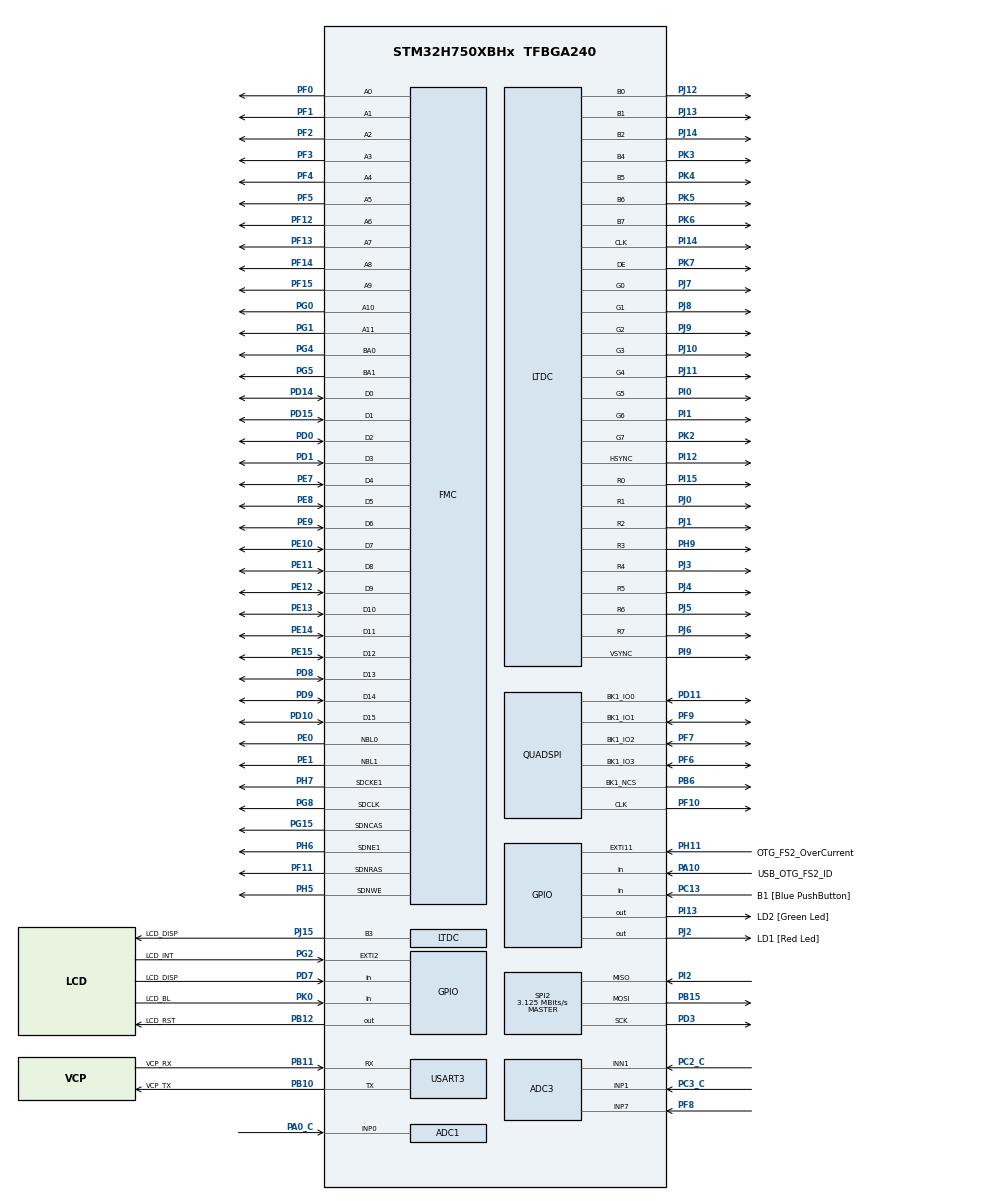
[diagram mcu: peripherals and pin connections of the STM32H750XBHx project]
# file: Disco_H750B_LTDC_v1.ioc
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ADC1.Channel-0\#ChannelRegularConversion=ADC_CHANNEL_0
ADC1.NbrOfConversionFlag=1
ADC1.OffsetNumber-0\#ChannelRegularConversion=ADC_OFFSET_NONE
ADC1.Rank-0\#ChannelRegularConversion=1
ADC1.SamplingTime-0\#ChannelRegularConversion=ADC_SAMPLETIME_1CYCLE_5
ADC1.master=1
ADC2.Channel-0\#ChannelRegularConversion=ADC_CHANNEL_0
ADC2.NbrOfConversionFlag=1
ADC2.OffsetNumber-0\#ChannelRegularConversion=ADC_OFFSET_NONE
ADC2.Rank-0\#ChannelRegularConversion=1
ADC2.SamplingTime-0\#ChannelRegularConversion=ADC_SAMPLETIME_1CYCLE_5
ADC3.Channel-0\#ChannelRegularConversion=ADC_CHANNEL_7
ADC3.NbrOfConversionFlag=1
ADC3.OffsetNumber-0\#ChannelRegularConversion=ADC_OFFSET_NONE
ADC3.Rank-0\#ChannelRegularConversion=1
ADC3.SamplingTime-0\#ChannelRegularConversion=ADC_SAMPLETIME_1CYCLE_5
Mcu.Family=STM32H7
Mcu.Name=STM32H750XBHx
Mcu.Package=TFBGA240
NVIC.PriorityGroup=NVIC_PRIORITYGROUP_4
PA0_C.Signal=ADCx_INP0
PA1.GPIO_Label=MII_RX_CLK
PA1.Signal=ETH_RX_CLK
PA10.GPIO_Label=USB_OTG_FS2_ID
PA10.Signal=GPIO_Input
PA11.GPIO_Label=USB_OTG_FS2_N
PA11.Signal=USB_OTG_FS_DM
PA12.GPIO_Label=USB_OTG_FS2_P
PA12.Signal=USB_OTG_FS_DP
PA1_C.Signal=ADCx_INP1
PA2.GPIO_Label=MII_MDIO
PA2.Signal=ETH_MDIO
PA6.Signal=S_TIM13_CH1
PA7.GPIO_Label=MII_RX_DV
PA7.Signal=ETH_RX_DV
PA8.Signal=S_TIM1_CH1
PA9.GPIO_Label=VBUS_FS2
PA9.Signal=USB_OTG_FS_VBUS
PB0.GPIO_Label=MII_RX_D2
PB0.Signal=ETH_RXD2
PB1.GPIO_Label=MII_RX_D3
PB1.Signal=ETH_RXD3
PB10.GPIO_Label=VCP_TX
PB10.Mode=Asynchronous
PB10.Signal=USART3_TX
PB11.GPIO_Label=VCP_RX
PB11.Mode=Asynchronous
PB11.Signal=USART3_RX
PB12.GPIO_Label=LCD_RST
PB12.Signal=GPIO_Output
PB13.GPIO_Label=FDCAN2_TX
PB13.Signal=FDCAN2_TX
PB15.Mode=Full_Duplex_Master
PB15.Signal=SPI2_MOSI
PB4\ (NJTRST).Signal=SPI2_NSS
PB5.GPIO_Label=FDCAN2_RX
PB5.Signal=FDCAN2_RX
PB6.Mode=Single Bank 1
PB6.Signal=QUADSPI_BK1_NCS
PB8.GPIO_Label=SDIO1_D4
PB8.Signal=SDMMC1_D4
PB9.GPIO_Label=SDIO1_D5
PB9.Signal=SDMMC1_D5
PC0.Signal=ADCx_INP10
PC1.GPIO_Label=MII_MDC
PC1.Signal=ETH_MDC
PC10.GPIO_Label=SDIO1_D2
PC10.Signal=SDMMC1_D2
PC11.GPIO_Label=SDIO1_D3
PC11.Signal=SDMMC1_D3
PC12.GPIO_Label=SDIO1_CK
PC12.Signal=SDMMC1_CK
PC13.GPIO_Label=B1 [Blue PushButton]
PC13.Signal=GPIO_Input
PC14-OSC32_IN\ (OSC32_IN).GPIO_Label=OSC32_IN
PC14-OSC32_IN\ (OSC32_IN).Mode=LSE-External-Clock-Source
PC14-OSC32_IN\ (OSC32_IN).Signal=RCC_OSC32_IN
PC15-OSC32_OUT\ (OSC32_OUT).GPIO_Label=OSC32_OUT
PC15-OSC32_OUT\ (OSC32_OUT).Signal=RCC_OSC32_OUT
PC2.GPIO_Label=MII_TXD2
PC2.Signal=ETH_TXD2
PC2_C.Signal=SharedAnalog_PC2
PC3.GPIO_Label=MII_TX_CLK
PC3.Signal=ETH_TX_CLK
PC3_C.Mode=IN1-Differential
PC3_C.Signal=ADC3_INP1
PC4.GPIO_Label=MII_RXD0
PC4.Signal=ETH_RXD0
PC5.GPIO_Label=MII_RXD1
PC5.Signal=ETH_RXD1
PC6.GPIO_Label=SDIO1_D6
PC6.Signal=SDMMC1_D6
PC7.GPIO_Label=SDIO1_D7
PC7.Signal=SDMMC1_D7
PC8.GPIO_Label=SDIO1_D0
PC8.Signal=SDMMC1_D0
PC9.GPIO_Label=SDIO1_D1
PC9.Signal=SDMMC1_D1
PD0.Signal=FMC_D2_DA2
PD1.Signal=FMC_D3_DA3
PD10.Signal=FMC_D15_DA15
PD11.Mode=Single Bank 1
PD11.Signal=QUADSPI_BK1_IO0
PD14.Signal=FMC_D0_DA0
PD15.Signal=FMC_D1_DA1
PD2.GPIO_Label=SDIO1_CMD
PD2.Signal=SDMMC1_CMD
PD3.Mode=Full_Duplex_Master
PD3.Signal=SPI2_SCK
PD7.GPIO_Label=LCD_DISP
PD7.Signal=GPIO_Input
PD8.Signal=FMC_D13_DA13
PD9.Signal=FMC_D14_DA14
PE0.Signal=FMC_NBL0
PE1.Signal=FMC_NBL1
PE10.Signal=FMC_D7_DA7
PE11.Signal=FMC_D8_DA8
PE12.Signal=FMC_D9_DA9
PE13.Signal=FMC_D10_DA10
PE14.Signal=FMC_D11_DA11
PE15.Signal=FMC_D12_DA12
PE2.GPIO_Label=MII_TXD3
PE2.Signal=ETH_TXD3
PE4.Signal=SAI4_D2
PE5.Signal=SAI4_CK2
PE7.Signal=FMC_D4_DA4
PE8.Signal=FMC_D5_DA5
PE9.Signal=FMC_D6_DA6
PF0.Signal=FMC_A0
PF1.Signal=FMC_A1
PF10.Mode=Single Bank 1
PF10.Signal=QUADSPI_CLK
PF11.Signal=FMC_SDNRAS
PF12.Signal=FMC_A6
PF13.Signal=FMC_A7
PF14.Signal=FMC_A8
PF15.Signal=FMC_A9
PF2.Signal=FMC_A2
PF3.Signal=FMC_A3
PF4.Signal=FMC_A4
PF5.Signal=FMC_A5
PF6.Mode=Single Bank 1
PF6.Signal=QUADSPI_BK1_IO3
PF7.Mode=Single Bank 1
PF7.Signal=QUADSPI_BK1_IO2
PF8.Mode=IN7-Single-Ended
PF8.Signal=ADC3_INP7
PF9.Mode=Single Bank 1
PF9.Signal=QUADSPI_BK1_IO1
PG0.Signal=FMC_A10
PG1.Signal=FMC_A11
PG10.Signal=SAI2_SD_B
PG11.GPIO_Label=MII_TX_EN
PG11.Signal=ETH_TX_EN
PG12.GPIO_Label=MII_TXD1
PG12.Signal=ETH_TXD1
PG13.GPIO_Label=MII_TXD0
PG13.Signal=ETH_TXD0
PG15.Signal=FMC_SDNCAS
PG2.GPIO_Label=LCD_INT
PG2.Signal=GPXTI2
PG4.Signal=FMC_A14_BA0
PG5.Signal=FMC_A15_BA1
PG8.Signal=FMC_SDCLK
PH0-OSC_IN\ (PH0).GPIO_Label=OSC_IN
PH0-OSC_IN\ (PH0).Mode=HSE-External-Clock-Source
PH0-OSC_IN\ (PH0).Signal=RCC_OSC_IN
PH1-OSC_OUT\ (PH1).GPIO_Label=OSC_OUT
PH1-OSC_OUT\ (PH1).Signal=RCC_OSC_OUT
PH11.GPIO_Label=OTG_FS2_OverCurrent
PH11.Signal=GPXTI11
PH13.GPIO_Label=FDCAN1_TX
PH13.Signal=FDCAN1_TX
PH14.GPIO_Label=FDCAN1_RX
PH14.Signal=FDCAN1_RX
PH15.Signal=TIM8_CH3N
PH2.GPIO_Label=MII_CRS
PH2.Signal=ETH_CRS
PH3.GPIO_Label=MII_COL
PH3.Signal=ETH_COL
PH5.Signal=FMC_SDNWE
PH6.Mode=SdramChipSelect2_1
PH6.Signal=FMC_SDNE1
PH7.Mode=SdramChipSelect2_1
PH7.Signal=FMC_SDCKE1
PH9.Mode=RGB888
PH9.Signal=LTDC_R3
PI0.Mode=RGB888
PI0.Signal=LTDC_G5
PI1.Mode=RGB888
PI1.Signal=LTDC_G6
PI10.GPIO_Label=MII_RX_ER
PI10.Signal=ETH_RX_ER
PI12.Mode=RGB888
PI12.Signal=LTDC_HSYNC
PI13.GPIO_Label=LD2 [Green Led]
PI13.Signal=GPIO_Output
PI14.Mode=RGB888
PI14.Signal=LTDC_CLK
PI15.Mode=RGB888
PI15.Signal=LTDC_R0
PI2.Mode=Full_Duplex_Master
PI2.Signal=SPI2_MISO
PI4.Signal=SAI2_MCLK_A
PI5.Signal=SAI2_SCK_A
PI6.Signal=SAI2_SD_A
PI7.Signal=SAI2_FS_A
PI9.Mode=RGB888
PI9.Signal=LTDC_VSYNC
PJ0.Mode=RGB888
PJ0.Signal=LTDC_R1
PJ1.Mode=RGB888
PJ1.Signal=LTDC_R2
PJ10.Mode=RGB888
PJ10.Signal=LTDC_G3
PJ11.Mode=RGB888
PJ11.Signal=LTDC_G4
PJ12.Mode=RGB888
PJ12.Signal=LTDC_B0
PJ13.Mode=RGB888
PJ13.Signal=LTDC_B1
PJ14.Mode=RGB888
PJ14.Signal=LTDC_B2
PJ15.GPIO_Label=LCD_DISP
PJ15.Mode=RGB888
PJ15.Signal=LTDC_B3
PJ2.GPIO_Label=LD1 [Red Led]
PJ2.Signal=GPIO_Output
PJ3.Mode=RGB888
PJ3.Signal=LTDC_R4
PJ4.Mode=RGB888
PJ4.Signal=LTDC_R5
PJ5.Mode=RGB888
PJ5.Signal=LTDC_R6
PJ6.Mode=RGB888
PJ6.Signal=LTDC_R7
PJ7.Mode=RGB888
PJ7.Signal=LTDC_G0
PJ8.Mode=RGB888
PJ8.Signal=LTDC_G1
PJ9.Mode=RGB888
PJ9.Signal=LTDC_G2
PK0.GPIO_Label=LCD_BL
PK0.Signal=GPIO_Input
PK2.Mode=RGB888
PK2.Signal=LTDC_G7
PK3.Mode=RGB888
PK3.Signal=LTDC_B4
PK4.Mode=RGB888
PK4.Signal=LTDC_B5
PK5.Mode=RGB888
PK5.Signal=LTDC_B6
PK6.Mode=RGB888
PK6.Signal=LTDC_B7
PK7.Mode=RGB888
PK7.Signal=LTDC_DE
ProjectManager.HeapSize=0x200
ProjectManager.StackSize=0x400
ProjectManager.TargetToolchain=STM32CubeIDE
RCC.ADCFreq_Value=30000000
RCC.APB1Freq_Value=100000000
RCC.APB2Freq_Value=100000000
RCC.APB3Freq_Value=100000000
RCC.APB4Freq_Value=100000000
RCC.CortexFreq_Value=200000000
RCC.DIVM1=10
RCC.DIVM2=2
RCC.DIVN1=160
RCC.DIVN2=12
RCC.DIVN3=192
RCC.DIVP2=5
RCC.DIVQ1=4
RCC.HCLKFreq_Value=100000000
RCC.HPRE=RCC_HCLK_DIV2
RCC.PLL2FRACN=0
RCC.PLL3FRACN=0
RCC.PLLFRACN=0
RCC.PLLSourceVirtual=RCC_PLLSOURCE_HSE
RCC.PWR_Regulator_Voltage_Scale=PWR_REGULATOR_VOLTAGE_SCALE2
RCC.SYSCLKFreq_VALUE=200000000
RCC.SYSCLKSource=RCC_SYSCLKSOURCE_PLLCLK
RCC.USART234578CLockSelection=RCC_USART234578CLKSOURCE_HSI
RCC.USBFreq_Value=100000000
SH.ADCx_INP0.0=ADC1_INP0,IN0-Single-Ended
SH.ADCx_INP0.1=ADC2_INP0,IN0-Single-Ended
SH.ADCx_INP1.0=ADC1_INP1
SH.ADCx_INP1.1=ADC2_INP1
SH.ADCx_INP10.0=ADC1_INP10
SH.ADCx_INP10.1=ADC3_INP10
SH.FMC_A0.0=FMC_A0,12b-sda1
SH.FMC_A1.0=FMC_A1,12b-sda1
SH.FMC_A10.0=FMC_A10,12b-sda1
SH.FMC_A11.0=FMC_A11,12b-sda1
SH.FMC_A14_BA0.0=FMC_BA0,FourSdramBanks1
SH.FMC_A15_BA1.0=FMC_BA1,FourSdramBanks1
SH.FMC_A2.0=FMC_A2,12b-sda1
SH.FMC_A3.0=FMC_A3,12b-sda1
SH.FMC_A4.0=FMC_A4,12b-sda1
SH.FMC_A5.0=FMC_A5,12b-sda1
SH.FMC_A6.0=FMC_A6,12b-sda1
SH.FMC_A7.0=FMC_A7,12b-sda1
SH.FMC_A8.0=FMC_A8,12b-sda1
SH.FMC_A9.0=FMC_A9,12b-sda1
SH.FMC_D0_DA0.0=FMC_D0,sd-16b-d1
SH.FMC_D10_DA10.0=FMC_D10,sd-16b-d1
SH.FMC_D11_DA11.0=FMC_D11,sd-16b-d1
SH.FMC_D12_DA12.0=FMC_D12,sd-16b-d1
SH.FMC_D13_DA13.0=FMC_D13,sd-16b-d1
SH.FMC_D14_DA14.0=FMC_D14,sd-16b-d1
SH.FMC_D15_DA15.0=FMC_D15,sd-16b-d1
SH.FMC_D1_DA1.0=FMC_D1,sd-16b-d1
SH.FMC_D2_DA2.0=FMC_D2,sd-16b-d1
SH.FMC_D3_DA3.0=FMC_D3,sd-16b-d1
SH.FMC_D4_DA4.0=FMC_D4,sd-16b-d1
SH.FMC_D5_DA5.0=FMC_D5,sd-16b-d1
SH.FMC_D6_DA6.0=FMC_D6,sd-16b-d1
SH.FMC_D7_DA7.0=FMC_D7,sd-16b-d1
SH.FMC_D8_DA8.0=FMC_D8,sd-16b-d1
SH.FMC_D9_DA9.0=FMC_D9,sd-16b-d1
SH.FMC_NBL0.0=FMC_NBL0,Sd2ByteEnable1
SH.FMC_NBL1.0=FMC_NBL1,Sd2ByteEnable1
SH.FMC_SDCLK.0=FMC_SDCLK,12b-sda1
SH.FMC_SDNCAS.0=FMC_SDNCAS,12b-sda1
SH.FMC_SDNRAS.0=FMC_SDNRAS,12b-sda1
SH.FMC_SDNWE.0=FMC_SDNWE,12b-sda1
SH.S_TIM13_CH1.0=TIM13_CH1
SH.S_TIM1_CH1.0=TIM1_CH1
SH.SharedAnalog_PC2.0=ADC3_INP0
SH.SharedAnalog_PC2.1=ADC3_INN1,IN1-Differential
SPI2.BaudRatePrescaler=SPI_BAUDRATEPRESCALER_32
SPI2.CalculateBaudRate=3.125 MBits/s
SPI2.DataSize=SPI_DATASIZE_8BIT
SPI2.Direction=SPI_DIRECTION_2LINES
SPI2.Mode=SPI_MODE_MASTER
SPI2.VirtualType=VM_MASTER
USART3.VirtualMode-Asynchronous=VM_ASYNC
VP_DMA2D_VS_DMA2D.Mode=DMA2D_Activate
board=STM32H750B-DK

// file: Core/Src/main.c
/* USER CODE BEGIN Header */
/**
  ******************************************************************************
  * @file           : main.c
  * @brief          : Main program body
  ******************************************************************************
  * @attention
  *
  * Copyright (c) 2022 STMicroelectronics.
  * All rights reserved.
  *
  * This software is licensed under terms that can be found in the LICENSE file
  * in the root directory of this software component.
  * If no LICENSE file comes with this software, it is provided AS-IS.
  *
  ******************************************************************************
  */
/* USER CODE END Header */
#include "main.h"

/* USER CODE BEGIN Includes */
#include <stdio.h>
#include "RGB565_320x240.h"
#include "L8_320x240.h"
/* USER CODE END Includes */

ADC_HandleTypeDef hadc1;
ADC_HandleTypeDef hadc2;
ADC_HandleTypeDef hadc3;

SPI_HandleTypeDef hspi2;

UART_HandleTypeDef huart3;

/* USER CODE BEGIN PV */
LTDC_HandleTypeDef LtdcHandle;

__IO uint32_t ReloadFlag = 0;

/* Pictures position */
uint32_t Xpos1 = 0;
uint32_t Xpos2 = 160;
uint32_t Ypos1 = 0;
uint32_t Ypos2 = 32;
/* USER CODE END PV */

void SystemClock_Config(void);
void PeriphCommonClock_Config(void);
static void MX_GPIO_Init(void);
static void MX_ADC1_Init(void);
static void MX_ADC2_Init(void);
static void MX_ADC3_Init(void);
static void MX_USART3_UART_Init(void);
static void MX_SPI2_Init(void);
/* USER CODE BEGIN PFP */
static void LCD_Config(void);
static void CPU_CACHE_Enable(void);
static void PicturesPosition(uint32_t* x1,
                         uint32_t* y1,
                         uint32_t* x2,
                         uint32_t* y2,
                         uint32_t index);

/* USER CODE END PFP */

/* USER CODE BEGIN 0 */
// WARNING UART3 is connected to st-link
// Properties -> Settings -> MCU_Settings -> select use float with printf
/*
 * USART6, BaudRate = 115200, WordLength = UART_WORDLENGTH_8B, StopBits = UART_STOPBITS_1;
 * */
int _write(int file, char *ptr, int len)
{
	HAL_UART_Transmit(&huart3,(uint8_t *)ptr, len, 10);
	return len;
}
/* USER CODE END 0 */

int main(void)
{
  /* USER CODE BEGIN 1 */
	 CPU_CACHE_Enable();
  /* USER CODE END 1 */

  /* MCU Configuration--------------------------------------------------------*/

  /* Reset of all peripherals, Initializes the Flash interface and the Systick. */
  HAL_Init();

  /* Configure the system clock */
  SystemClock_Config();

/* Configure the peripherals common clocks */
  PeriphCommonClock_Config();

  /* Initialize all configured peripherals */
  MX_GPIO_Init();
  MX_ADC1_Init();
  MX_ADC2_Init();
  MX_ADC3_Init();
  MX_USART3_UART_Init();
  MX_SPI2_Init();
  /* USER CODE BEGIN 2 */

  /* Configure LED2 */
  BSP_LED_Init(LED2);

  /*##-1- LCD Configuration ##################################################*/
  /* Configure 2 layers w/ Blending and CLUT loading for layer 1 */
  LCD_Config();

  /*##-2- CLUT Configuration #################################################*/
  HAL_LTDC_ConfigCLUT(&LtdcHandle, (uint32_t *)L8_320x240_CLUT, 256, 0);

  /*##-3- Enable CLUT For Layer 1 ############################################*/
  HAL_LTDC_EnableCLUT(&LtdcHandle, 0);

  /* USER CODE END 2 */

  /* Infinite loop */
  while (1)
  {

    /* USER CODE BEGIN 3 */
	  printf("inf loop\n");
	  for (int index = 0; index < 32; index++)
	    {
	      /* calculate new picture position */
	       PicturesPosition(&Xpos1, &Ypos1, &Xpos2, &Ypos2, (index+1));

	       /* reconfigure the layer1 position  without Reloading*/
	       HAL_LTDC_SetWindowPosition_NoReload(&LtdcHandle, Xpos1, Ypos1, 0);
	       /* reconfigure the layer2 position  without Reloading*/
	       HAL_LTDC_SetWindowPosition_NoReload(&LtdcHandle, Xpos2, Ypos2, 1);
	       /*Ask for LTDC reload within next vertical blanking*/
	       ReloadFlag = 0;
	       HAL_LTDC_Reload(&LtdcHandle,LTDC_RELOAD_VERTICAL_BLANKING);

	      while(ReloadFlag == 0)
	      {
	        /* wait till reload takes effect (in the next vertical blanking period) */
	      }
	    }
	    HAL_Delay(500);

	    for (int index = 0; index < 32; index++)
	    {
	      /* calculate new picture position */
	       PicturesPosition(&Xpos2, &Ypos2, &Xpos1, &Ypos1, (index+1));

	       /* reconfigure the layer1 position  without Reloading*/
	       HAL_LTDC_SetWindowPosition_NoReload(&LtdcHandle, Xpos1, Ypos1, 0);
	       /* reconfigure the layer2 position  without Reloading*/
	       HAL_LTDC_SetWindowPosition_NoReload(&LtdcHandle, Xpos2, Ypos2, 1);
	       /*Ask for LTDC reload within next vertical blanking*/
	       ReloadFlag = 0;
	       HAL_LTDC_Reload(&LtdcHandle,LTDC_RELOAD_VERTICAL_BLANKING);

	      while(ReloadFlag == 0)
	    {
	        /* wait till reload takes effect (in the next vertical blanking period) */
	    }
	  }
	    HAL_Delay(500);
	  }
  /* USER CODE END 3 */
}

void SystemClock_Config(void)
{
  RCC_OscInitTypeDef RCC_OscInitStruct = {0};
  RCC_ClkInitTypeDef RCC_ClkInitStruct = {0};

  /** Supply configuration update enable
  */
  HAL_PWREx_ConfigSupply(PWR_LDO_SUPPLY);

  /** Configure the main internal regulator output voltage
  */
  __HAL_PWR_VOLTAGESCALING_CONFIG(PWR_REGULATOR_VOLTAGE_SCALE2);

  while(!__HAL_PWR_GET_FLAG(PWR_FLAG_VOSRDY)) {}

  /** Macro to configure the PLL clock source
  */
  __HAL_RCC_PLL_PLLSOURCE_CONFIG(RCC_PLLSOURCE_HSE);

  /** Initializes the RCC Oscillators according to the specified parameters
  * in the RCC_OscInitTypeDef structure.
  */
  RCC_OscInitStruct.OscillatorType = RCC_OSCILLATORTYPE_HSI|RCC_OSCILLATORTYPE_HSE;
  RCC_OscInitStruct.HSEState = RCC_HSE_BYPASS;
  RCC_OscInitStruct.HSIState = RCC_HSI_DIV1;
  RCC_OscInitStruct.HSICalibrationValue = RCC_HSICALIBRATION_DEFAULT;
  RCC_OscInitStruct.PLL.PLLState = RCC_PLL_ON;
  RCC_OscInitStruct.PLL.PLLSource = RCC_PLLSOURCE_HSE;
  RCC_OscInitStruct.PLL.PLLM = 10;
  RCC_OscInitStruct.PLL.PLLN = 160;
  RCC_OscInitStruct.PLL.PLLP = 2;
  RCC_OscInitStruct.PLL.PLLQ = 4;
  RCC_OscInitStruct.PLL.PLLR = 2;
  RCC_OscInitStruct.PLL.PLLRGE = RCC_PLL1VCIRANGE_1;
  RCC_OscInitStruct.PLL.PLLVCOSEL = RCC_PLL1VCOWIDE;
  RCC_OscInitStruct.PLL.PLLFRACN = 0;
  if (HAL_RCC_OscConfig(&RCC_OscInitStruct) != HAL_OK)
  {
    Error_Handler();
  }

  /** Initializes the CPU, AHB and APB buses clocks
  */
  RCC_ClkInitStruct.ClockType = RCC_CLOCKTYPE_HCLK|RCC_CLOCKTYPE_SYSCLK
                              |RCC_CLOCKTYPE_PCLK1|RCC_CLOCKTYPE_PCLK2
                              |RCC_CLOCKTYPE_D3PCLK1|RCC_CLOCKTYPE_D1PCLK1;
  RCC_ClkInitStruct.SYSCLKSource = RCC_SYSCLKSOURCE_PLLCLK;
  RCC_ClkInitStruct.SYSCLKDivider = RCC_SYSCLK_DIV1;
  RCC_ClkInitStruct.AHBCLKDivider = RCC_HCLK_DIV2;
  RCC_ClkInitStruct.APB3CLKDivider = RCC_APB3_DIV1;
  RCC_ClkInitStruct.APB1CLKDivider = RCC_APB1_DIV1;
  RCC_ClkInitStruct.APB2CLKDivider = RCC_APB2_DIV1;
  RCC_ClkInitStruct.APB4CLKDivider = RCC_APB4_DIV1;

  if (HAL_RCC_ClockConfig(&RCC_ClkInitStruct, FLASH_LATENCY_1) != HAL_OK)
  {
    Error_Handler();
  }
}

void PeriphCommonClock_Config(void)
{
  RCC_PeriphCLKInitTypeDef PeriphClkInitStruct = {0};

  /** Initializes the peripherals clock
  */
  PeriphClkInitStruct.PeriphClockSelection = RCC_PERIPHCLK_ADC;
  PeriphClkInitStruct.PLL2.PLL2M = 2;
  PeriphClkInitStruct.PLL2.PLL2N = 12;
  PeriphClkInitStruct.PLL2.PLL2P = 5;
  PeriphClkInitStruct.PLL2.PLL2Q = 2;
  PeriphClkInitStruct.PLL2.PLL2R = 2;
  PeriphClkInitStruct.PLL2.PLL2RGE = RCC_PLL2VCIRANGE_3;
  PeriphClkInitStruct.PLL2.PLL2VCOSEL = RCC_PLL2VCOMEDIUM;
  PeriphClkInitStruct.PLL2.PLL2FRACN = 0;
  PeriphClkInitStruct.AdcClockSelection = RCC_ADCCLKSOURCE_PLL2;
  if (HAL_RCCEx_PeriphCLKConfig(&PeriphClkInitStruct) != HAL_OK)
  {
    Error_Handler();
  }
}

static void MX_ADC1_Init(void)
{

  ADC_MultiModeTypeDef multimode = {0};
  ADC_ChannelConfTypeDef sConfig = {0};

  /** Common config
  */
  hadc1.Instance = ADC1;
  hadc1.Init.ClockPrescaler = ADC_CLOCK_ASYNC_DIV2;
  hadc1.Init.Resolution = ADC_RESOLUTION_16B;
  hadc1.Init.ScanConvMode = ADC_SCAN_DISABLE;
  hadc1.Init.EOCSelection = ADC_EOC_SINGLE_CONV;
  hadc1.Init.LowPowerAutoWait = DISABLE;
  hadc1.Init.ContinuousConvMode = DISABLE;
  hadc1.Init.NbrOfConversion = 1;
  hadc1.Init.DiscontinuousConvMode = DISABLE;
  hadc1.Init.ExternalTrigConv = ADC_SOFTWARE_START;
  hadc1.Init.ExternalTrigConvEdge = ADC_EXTERNALTRIGCONVEDGE_NONE;
  hadc1.Init.ConversionDataManagement = ADC_CONVERSIONDATA_DR;
  hadc1.Init.Overrun = ADC_OVR_DATA_PRESERVED;
  hadc1.Init.LeftBitShift = ADC_LEFTBITSHIFT_NONE;
  hadc1.Init.OversamplingMode = DISABLE;
  if (HAL_ADC_Init(&hadc1) != HAL_OK)
  {
    Error_Handler();
  }

  /** Configure the ADC multi-mode
  */
  multimode.Mode = ADC_MODE_INDEPENDENT;
  if (HAL_ADCEx_MultiModeConfigChannel(&hadc1, &multimode) != HAL_OK)
  {
    Error_Handler();
  }

  /** Configure Regular Channel
  */
  sConfig.Channel = ADC_CHANNEL_0;
  sConfig.Rank = ADC_REGULAR_RANK_1;
  sConfig.SamplingTime = ADC_SAMPLETIME_1CYCLE_5;
  sConfig.SingleDiff = ADC_SINGLE_ENDED;
  sConfig.OffsetNumber = ADC_OFFSET_NONE;
  sConfig.Offset = 0;
  sConfig.OffsetSignedSaturation = DISABLE;
  if (HAL_ADC_ConfigChannel(&hadc1, &sConfig) != HAL_OK)
  {
    Error_Handler();
  }

}

static void MX_ADC2_Init(void)
{

  ADC_ChannelConfTypeDef sConfig = {0};

  /** Common config
  */
  hadc2.Instance = ADC2;
  hadc2.Init.ClockPrescaler = ADC_CLOCK_ASYNC_DIV2;
  hadc2.Init.Resolution = ADC_RESOLUTION_16B;
  hadc2.Init.ScanConvMode = ADC_SCAN_DISABLE;
  hadc2.Init.EOCSelection = ADC_EOC_SINGLE_CONV;
  hadc2.Init.LowPowerAutoWait = DISABLE;
  hadc2.Init.ContinuousConvMode = DISABLE;
  hadc2.Init.NbrOfConversion = 1;
  hadc2.Init.DiscontinuousConvMode = DISABLE;
  hadc2.Init.ExternalTrigConv = ADC_SOFTWARE_START;
  hadc2.Init.ExternalTrigConvEdge = ADC_EXTERNALTRIGCONVEDGE_NONE;
  hadc2.Init.ConversionDataManagement = ADC_CONVERSIONDATA_DR;
  hadc2.Init.Overrun = ADC_OVR_DATA_PRESERVED;
  hadc2.Init.LeftBitShift = ADC_LEFTBITSHIFT_NONE;
  hadc2.Init.OversamplingMode = DISABLE;
  if (HAL_ADC_Init(&hadc2) != HAL_OK)
  {
    Error_Handler();
  }

  /** Configure Regular Channel
  */
  sConfig.Channel = ADC_CHANNEL_0;
  sConfig.Rank = ADC_REGULAR_RANK_1;
  sConfig.SamplingTime = ADC_SAMPLETIME_1CYCLE_5;
  sConfig.SingleDiff = ADC_SINGLE_ENDED;
  sConfig.OffsetNumber = ADC_OFFSET_NONE;
  sConfig.Offset = 0;
  sConfig.OffsetSignedSaturation = DISABLE;
  if (HAL_ADC_ConfigChannel(&hadc2, &sConfig) != HAL_OK)
  {
    Error_Handler();
  }

}

static void MX_ADC3_Init(void)
{

  ADC_ChannelConfTypeDef sConfig = {0};

  /** Common config
  */
  hadc3.Instance = ADC3;
  hadc3.Init.Resolution = ADC_RESOLUTION_16B;
  hadc3.Init.ScanConvMode = ADC_SCAN_DISABLE;
  hadc3.Init.EOCSelection = ADC_EOC_SINGLE_CONV;
  hadc3.Init.LowPowerAutoWait = DISABLE;
  hadc3.Init.ContinuousConvMode = DISABLE;
  hadc3.Init.NbrOfConversion = 1;
  hadc3.Init.DiscontinuousConvMode = DISABLE;
  hadc3.Init.ExternalTrigConv = ADC_SOFTWARE_START;
  hadc3.Init.ExternalTrigConvEdge = ADC_EXTERNALTRIGCONVEDGE_NONE;
  hadc3.Init.ConversionDataManagement = ADC_CONVERSIONDATA_DR;
  hadc3.Init.Overrun = ADC_OVR_DATA_PRESERVED;
  hadc3.Init.LeftBitShift = ADC_LEFTBITSHIFT_NONE;
  hadc3.Init.OversamplingMode = DISABLE;
  if (HAL_ADC_Init(&hadc3) != HAL_OK)
  {
    Error_Handler();
  }

  /** Configure Regular Channel
  */
  sConfig.Channel = ADC_CHANNEL_7;
  sConfig.Rank = ADC_REGULAR_RANK_1;
  sConfig.SamplingTime = ADC_SAMPLETIME_1CYCLE_5;
  sConfig.SingleDiff = ADC_SINGLE_ENDED;
  sConfig.OffsetNumber = ADC_OFFSET_NONE;
  sConfig.Offset = 0;
  sConfig.OffsetSignedSaturation = DISABLE;
  if (HAL_ADC_ConfigChannel(&hadc3, &sConfig) != HAL_OK)
  {
    Error_Handler();
  }

}

static void MX_SPI2_Init(void)
{

  /* SPI2 parameter configuration*/
  hspi2.Instance = SPI2;
  hspi2.Init.Mode = SPI_MODE_MASTER;
  hspi2.Init.Direction = SPI_DIRECTION_2LINES;
  hspi2.Init.DataSize = SPI_DATASIZE_8BIT;
  hspi2.Init.CLKPolarity = SPI_POLARITY_LOW;
  hspi2.Init.CLKPhase = SPI_PHASE_1EDGE;
  hspi2.Init.NSS = SPI_NSS_SOFT;
  hspi2.Init.BaudRatePrescaler = SPI_BAUDRATEPRESCALER_32;
  hspi2.Init.FirstBit = SPI_FIRSTBIT_MSB;
  hspi2.Init.TIMode = SPI_TIMODE_DISABLE;
  hspi2.Init.CRCCalculation = SPI_CRCCALCULATION_DISABLE;
  hspi2.Init.CRCPolynomial = 0x0;
  hspi2.Init.NSSPMode = SPI_NSS_PULSE_ENABLE;
  hspi2.Init.NSSPolarity = SPI_NSS_POLARITY_LOW;
  hspi2.Init.FifoThreshold = SPI_FIFO_THRESHOLD_01DATA;
  hspi2.Init.TxCRCInitializationPattern = SPI_CRC_INITIALIZATION_ALL_ZERO_PATTERN;
  hspi2.Init.RxCRCInitializationPattern = SPI_CRC_INITIALIZATION_ALL_ZERO_PATTERN;
  hspi2.Init.MasterSSIdleness = SPI_MASTER_SS_IDLENESS_00CYCLE;
  hspi2.Init.MasterInterDataIdleness = SPI_MASTER_INTERDATA_IDLENESS_00CYCLE;
  hspi2.Init.MasterReceiverAutoSusp = SPI_MASTER_RX_AUTOSUSP_DISABLE;
  hspi2.Init.MasterKeepIOState = SPI_MASTER_KEEP_IO_STATE_DISABLE;
  hspi2.Init.IOSwap = SPI_IO_SWAP_DISABLE;
  if (HAL_SPI_Init(&hspi2) != HAL_OK)
  {
    Error_Handler();
  }

}

static void MX_USART3_UART_Init(void)
{

  huart3.Instance = USART3;
  huart3.Init.BaudRate = 115200;
  huart3.Init.WordLength = UART_WORDLENGTH_8B;
  huart3.Init.StopBits = UART_STOPBITS_1;
  huart3.Init.Parity = UART_PARITY_NONE;
  huart3.Init.Mode = UART_MODE_TX_RX;
  huart3.Init.HwFlowCtl = UART_HWCONTROL_NONE;
  huart3.Init.OverSampling = UART_OVERSAMPLING_16;
  huart3.Init.OneBitSampling = UART_ONE_BIT_SAMPLE_DISABLE;
  huart3.Init.ClockPrescaler = UART_PRESCALER_DIV1;
  huart3.AdvancedInit.AdvFeatureInit = UART_ADVFEATURE_NO_INIT;
  if (HAL_UART_Init(&huart3) != HAL_OK)
  {
    Error_Handler();
  }
  if (HAL_UARTEx_SetTxFifoThreshold(&huart3, UART_TXFIFO_THRESHOLD_1_8) != HAL_OK)
  {
    Error_Handler();
  }
  if (HAL_UARTEx_SetRxFifoThreshold(&huart3, UART_RXFIFO_THRESHOLD_1_8) != HAL_OK)
  {
    Error_Handler();
  }
  if (HAL_UARTEx_DisableFifoMode(&huart3) != HAL_OK)
  {
    Error_Handler();
  }

}

static void MX_GPIO_Init(void)
{
  GPIO_InitTypeDef GPIO_InitStruct = {0};

  /* GPIO Ports Clock Enable */
  __HAL_RCC_GPIOI_CLK_ENABLE();
  __HAL_RCC_GPIOB_CLK_ENABLE();
  __HAL_RCC_GPIOK_CLK_ENABLE();
  __HAL_RCC_GPIOG_CLK_ENABLE();
  __HAL_RCC_GPIOC_CLK_ENABLE();
  __HAL_RCC_GPIOE_CLK_ENABLE();
  __HAL_RCC_GPIOJ_CLK_ENABLE();
  __HAL_RCC_GPIOD_CLK_ENABLE();
  __HAL_RCC_GPIOH_CLK_ENABLE();
  __HAL_RCC_GPIOA_CLK_ENABLE();
  __HAL_RCC_GPIOF_CLK_ENABLE();

  /*Configure GPIO pin Output Level */
  HAL_GPIO_WritePin(LD2_GPIO_Port, LD2_Pin, GPIO_PIN_RESET);

  /*Configure GPIO pin Output Level */
  HAL_GPIO_WritePin(LD1_GPIO_Port, LD1_Pin, GPIO_PIN_RESET);

  /*Configure GPIO pin Output Level */
  HAL_GPIO_WritePin(LCD_RST_GPIO_Port, LCD_RST_Pin, GPIO_PIN_RESET);

  /*Configure GPIO pins : PI6 PI5 PI4 PI7 */
  GPIO_InitStruct.Pin = GPIO_PIN_6|GPIO_PIN_5|GPIO_PIN_4|GPIO_PIN_7;
  GPIO_InitStruct.Mode = GPIO_MODE_AF_PP;
  GPIO_InitStruct.Pull = GPIO_NOPULL;
  GPIO_InitStruct.Speed = GPIO_SPEED_FREQ_LOW;
  GPIO_InitStruct.Alternate = GPIO_AF10_SAI2;
  HAL_GPIO_Init(GPIOI, &GPIO_InitStruct);

  /*Configure GPIO pins : FDCAN2_RX_Pin FDCAN2_TX_Pin */
  GPIO_InitStruct.Pin = FDCAN2_RX_Pin|FDCAN2_TX_Pin;
  GPIO_InitStruct.Mode = GPIO_MODE_AF_PP;
  GPIO_InitStruct.Pull = GPIO_NOPULL;
  GPIO_InitStruct.Speed = GPIO_SPEED_FREQ_LOW;
  GPIO_InitStruct.Alternate = GPIO_AF9_FDCAN2;
  HAL_GPIO_Init(GPIOB, &GPIO_InitStruct);

  /*Configure GPIO pin : PG10 */
  GPIO_InitStruct.Pin = GPIO_PIN_10;
  GPIO_InitStruct.Mode = GPIO_MODE_AF_PP;
  GPIO_InitStruct.Pull = GPIO_NOPULL;
  GPIO_InitStruct.Speed = GPIO_SPEED_FREQ_LOW;
  GPIO_InitStruct.Alternate = GPIO_AF10_SAI2;
  HAL_GPIO_Init(GPIOG, &GPIO_InitStruct);

  /*Configure GPIO pins : SDIO1_D2_Pin SDIO1_D3_Pin SDIO1_CK_Pin SDIO1_D0_Pin
                           SDIO1_D1_Pin SDIO1_D7_Pin SDIO1_D6_Pin */
  GPIO_InitStruct.Pin = SDIO1_D2_Pin|SDIO1_D3_Pin|SDIO1_CK_Pin|SDIO1_D0_Pin
                          |SDIO1_D1_Pin|SDIO1_D7_Pin|SDIO1_D6_Pin;
  GPIO_InitStruct.Mode = GPIO_MODE_AF_PP;
  GPIO_InitStruct.Pull = GPIO_NOPULL;
  GPIO_InitStruct.Speed = GPIO_SPEED_FREQ_VERY_HIGH;
  GPIO_InitStruct.Alternate = GPIO_AF12_SDIO1;
  HAL_GPIO_Init(GPIOC, &GPIO_InitStruct);

  /*Configure GPIO pins : MII_TX_EN_Pin MII_TXD1_Pin MII_TXD0_Pin */
  GPIO_InitStruct.Pin = MII_TX_EN_Pin|MII_TXD1_Pin|MII_TXD0_Pin;
  GPIO_InitStruct.Mode = GPIO_MODE_AF_PP;
  GPIO_InitStruct.Pull = GPIO_NOPULL;
  GPIO_InitStruct.Speed = GPIO_SPEED_FREQ_LOW;
  GPIO_InitStruct.Alternate = GPIO_AF11_ETH;
  HAL_GPIO_Init(GPIOG, &GPIO_InitStruct);

  /*Configure GPIO pin : PH15 */
  GPIO_InitStruct.Pin = GPIO_PIN_15;
  GPIO_InitStruct.Mode = GPIO_MODE_AF_PP;
  GPIO_InitStruct.Pull = GPIO_NOPULL;
  GPIO_InitStruct.Speed = GPIO_SPEED_FREQ_LOW;
  GPIO_InitStruct.Alternate = GPIO_AF3_TIM8;
  HAL_GPIO_Init(GPIOH, &GPIO_InitStruct);

  /*Configure GPIO pins : FDCAN1_RX_Pin FDCAN1_TX_Pin */
  GPIO_InitStruct.Pin = FDCAN1_RX_Pin|FDCAN1_TX_Pin;
  GPIO_InitStruct.Mode = GPIO_MODE_AF_PP;
  GPIO_InitStruct.Pull = GPIO_NOPULL;
  GPIO_InitStruct.Speed = GPIO_SPEED_FREQ_LOW;
  GPIO_InitStruct.Alternate = GPIO_AF9_FDCAN1;
  HAL_GPIO_Init(GPIOH, &GPIO_InitStruct);

  /*Configure GPIO pin : MII_TXD3_Pin */
  GPIO_InitStruct.Pin = MII_TXD3_Pin;
  GPIO_InitStruct.Mode = GPIO_MODE_AF_PP;
  GPIO_InitStruct.Pull = GPIO_NOPULL;
  GPIO_InitStruct.Speed = GPIO_SPEED_FREQ_LOW;
  GPIO_InitStruct.Alternate = GPIO_AF11_ETH;
  HAL_GPIO_Init(MII_TXD3_GPIO_Port, &GPIO_InitStruct);

  /*Configure GPIO pin : LCD_DISPD7_Pin */
  GPIO_InitStruct.Pin = LCD_DISPD7_Pin;
  GPIO_InitStruct.Mode = GPIO_MODE_INPUT;
  GPIO_InitStruct.Pull = GPIO_NOPULL;
  HAL_GPIO_Init(LCD_DISPD7_GPIO_Port, &GPIO_InitStruct);

  /*Configure GPIO pins : PE5 PE4 */
  GPIO_InitStruct.Pin = GPIO_PIN_5|GPIO_PIN_4;
  GPIO_InitStruct.Mode = GPIO_MODE_AF_PP;
  GPIO_InitStruct.Pull = GPIO_NOPULL;
  GPIO_InitStruct.Speed = GPIO_SPEED_FREQ_LOW;
  GPIO_InitStruct.Alternate = GPIO_AF10_SAI4;
  HAL_GPIO_Init(GPIOE, &GPIO_InitStruct);

  /*Configure GPIO pins : SDIO1_D5_Pin SDIO1_D4_Pin */
  GPIO_InitStruct.Pin = SDIO1_D5_Pin|SDIO1_D4_Pin;
  GPIO_InitStruct.Mode = GPIO_MODE_AF_PP;
  GPIO_InitStruct.Pull = GPIO_NOPULL;
  GPIO_InitStruct.Speed = GPIO_SPEED_FREQ_VERY_HIGH;
  GPIO_InitStruct.Alternate = GPIO_AF12_SDIO1;
  HAL_GPIO_Init(GPIOB, &GPIO_InitStruct);

  /*Configure GPIO pin : SDIO1_CMD_Pin */
  GPIO_InitStruct.Pin = SDIO1_CMD_Pin;
  GPIO_InitStruct.Mode = GPIO_MODE_AF_PP;
  GPIO_InitStruct.Pull = GPIO_NOPULL;
  GPIO_InitStruct.Speed = GPIO_SPEED_FREQ_VERY_HIGH;
  GPIO_InitStruct.Alternate = GPIO_AF12_SDIO1;
  HAL_GPIO_Init(SDIO1_CMD_GPIO_Port, &GPIO_InitStruct);

  /*Configure GPIO pin : USB_OTG_FS2_ID_Pin */
  GPIO_InitStruct.Pin = USB_OTG_FS2_ID_Pin;
  GPIO_InitStruct.Mode = GPIO_MODE_INPUT;
  GPIO_InitStruct.Pull = GPIO_NOPULL;
  HAL_GPIO_Init(USB_OTG_FS2_ID_GPIO_Port, &GPIO_InitStruct);

  /*Configure GPIO pin : B1_Pin */
  GPIO_InitStruct.Pin = B1_Pin;
  GPIO_InitStruct.Mode = GPIO_MODE_INPUT;
  GPIO_InitStruct.Pull = GPIO_NOPULL;
  HAL_GPIO_Init(B1_GPIO_Port, &GPIO_InitStruct);

  /*Configure GPIO pin : PA8 */
  GPIO_InitStruct.Pin = GPIO_PIN_8;
  GPIO_InitStruct.Mode = GPIO_MODE_AF_PP;
  GPIO_InitStruct.Pull = GPIO_NOPULL;
  GPIO_InitStruct.Speed = GPIO_SPEED_FREQ_LOW;
  GPIO_InitStruct.Alternate = GPIO_AF1_TIM1;
  HAL_GPIO_Init(GPIOA, &GPIO_InitStruct);

  /*Configure GPIO pins : USB_OTG_FS2_P_Pin USB_OTG_FS2_N_Pin */
  GPIO_InitStruct.Pin = USB_OTG_FS2_P_Pin|USB_OTG_FS2_N_Pin;
  GPIO_InitStruct.Mode = GPIO_MODE_AF_PP;
  GPIO_InitStruct.Pull = GPIO_NOPULL;
  GPIO_InitStruct.Speed = GPIO_SPEED_FREQ_LOW;
  GPIO_InitStruct.Alternate = GPIO_AF10_OTG1_FS;
  HAL_GPIO_Init(GPIOA, &GPIO_InitStruct);

  /*Configure GPIO pin : MII_RX_ER_Pin */
  GPIO_InitStruct.Pin = MII_RX_ER_Pin;
  GPIO_InitStruct.Mode = GPIO_MODE_AF_PP;
  GPIO_InitStruct.Pull = GPIO_NOPULL;
  GPIO_InitStruct.Speed = GPIO_SPEED_FREQ_LOW;
  GPIO_InitStruct.Alternate = GPIO_AF11_ETH;
  HAL_GPIO_Init(MII_RX_ER_GPIO_Port, &GPIO_InitStruct);

  /*Configure GPIO pin : LD2_Pin */
  GPIO_InitStruct.Pin = LD2_Pin;
  GPIO_InitStruct.Mode = GPIO_MODE_OUTPUT_PP;
  GPIO_InitStruct.Pull = GPIO_NOPULL;
  GPIO_InitStruct.Speed = GPIO_SPEED_FREQ_LOW;
  HAL_GPIO_Init(LD2_GPIO_Port, &GPIO_InitStruct);

  /*Configure GPIO pin : LCD_INT_Pin */
  GPIO_InitStruct.Pin = LCD_INT_Pin;
  GPIO_InitStruct.Mode = GPIO_MODE_IT_RISING;
  GPIO_InitStruct.Pull = GPIO_NOPULL;
  HAL_GPIO_Init(LCD_INT_GPIO_Port, &GPIO_InitStruct);

  /*Configure GPIO pin : LCD_BL_Pin */
  GPIO_InitStruct.Pin = LCD_BL_Pin;
  GPIO_InitStruct.Mode = GPIO_MODE_INPUT;
  GPIO_InitStruct.Pull = GPIO_NOPULL;
  HAL_GPIO_Init(LCD_BL_GPIO_Port, &GPIO_InitStruct);

//  /*Configure GPIO pins : MII_MDC_Pin MII_TXD2_Pin MII_TX_CLK_Pin MII_RXD0_Pin
//                           MII_RXD1_Pin */
//  GPIO_InitStruct.Pin = MII_MDC_Pin|MII_TXD2_Pin|MII_TX_CLK_Pin|MII_RXD0_Pin
//                          |MII_RXD1_Pin;
//  GPIO_InitStruct.Mode = GPIO_MODE_AF_PP;
//  GPIO_InitStruct.Pull = GPIO_NOPULL;
//  GPIO_InitStruct.Speed = GPIO_SPEED_FREQ_LOW;
//  GPIO_InitStruct.Alternate = GPIO_AF11_ETH;
//  HAL_GPIO_Init(GPIOC, &GPIO_InitStruct);
//
//  /*Configure GPIO pins : MII_CRS_Pin MII_COL_Pin */
//  GPIO_InitStruct.Pin = MII_CRS_Pin|MII_COL_Pin;
//  GPIO_InitStruct.Mode = GPIO_MODE_AF_PP;
//  GPIO_InitStruct.Pull = GPIO_NOPULL;
//  GPIO_InitStruct.Speed = GPIO_SPEED_FREQ_LOW;
//  GPIO_InitStruct.Alternate = GPIO_AF11_ETH;
//  HAL_GPIO_Init(GPIOH, &GPIO_InitStruct);
//
//  /*Configure GPIO pins : MII_MDIO_Pin MII_RX_CLK_Pin MII_RX_DV_Pin */
//  GPIO_InitStruct.Pin = MII_MDIO_Pin|MII_RX_CLK_Pin|MII_RX_DV_Pin;
//  GPIO_InitStruct.Mode = GPIO_MODE_AF_PP;
//  GPIO_InitStruct.Pull = GPIO_NOPULL;
//  GPIO_InitStruct.Speed = GPIO_SPEED_FREQ_LOW;
//  GPIO_InitStruct.Alternate = GPIO_AF11_ETH;
//  HAL_GPIO_Init(GPIOA, &GPIO_InitStruct);

  /*Configure GPIO pin : OTG_FS2_OverCurrent_Pin */
  GPIO_InitStruct.Pin = OTG_FS2_OverCurrent_Pin;
  GPIO_InitStruct.Mode = GPIO_MODE_IT_RISING;
  GPIO_InitStruct.Pull = GPIO_NOPULL;
  HAL_GPIO_Init(OTG_FS2_OverCurrent_GPIO_Port, &GPIO_InitStruct);

  /*Configure GPIO pin : PA6 */
  GPIO_InitStruct.Pin = GPIO_PIN_6;
  GPIO_InitStruct.Mode = GPIO_MODE_AF_PP;
  GPIO_InitStruct.Pull = GPIO_NOPULL;
  GPIO_InitStruct.Speed = GPIO_SPEED_FREQ_LOW;
  GPIO_InitStruct.Alternate = GPIO_AF9_TIM13;
  HAL_GPIO_Init(GPIOA, &GPIO_InitStruct);

  /*Configure GPIO pins : MII_RX_D3_Pin MII_RX_D2_Pin */
  GPIO_InitStruct.Pin = MII_RX_D3_Pin|MII_RX_D2_Pin;
  GPIO_InitStruct.Mode = GPIO_MODE_AF_PP;
  GPIO_InitStruct.Pull = GPIO_NOPULL;
  GPIO_InitStruct.Speed = GPIO_SPEED_FREQ_LOW;
  GPIO_InitStruct.Alternate = GPIO_AF11_ETH;
  HAL_GPIO_Init(GPIOB, &GPIO_InitStruct);

  /*Configure GPIO pin : LD1_Pin */
  GPIO_InitStruct.Pin = LD1_Pin;
  GPIO_InitStruct.Mode = GPIO_MODE_OUTPUT_PP;
  GPIO_InitStruct.Pull = GPIO_NOPULL;
  GPIO_InitStruct.Speed = GPIO_SPEED_FREQ_LOW;
  HAL_GPIO_Init(LD1_GPIO_Port, &GPIO_InitStruct);

  /*Configure GPIO pin : LCD_RST_Pin */
  GPIO_InitStruct.Pin = LCD_RST_Pin;
  GPIO_InitStruct.Mode = GPIO_MODE_OUTPUT_PP;
  GPIO_InitStruct.Pull = GPIO_NOPULL;
  GPIO_InitStruct.Speed = GPIO_SPEED_FREQ_LOW;
  HAL_GPIO_Init(LCD_RST_GPIO_Port, &GPIO_InitStruct);

}

/* USER CODE BEGIN 4 */
/**
  * @brief  calculate pictures position.
  * @param  x1:    picture1 x position
  * @param  y1:    picture1 y position
  * @param  x2:    picture2 x position
  * @param  y2:    picture2 y position
  * @param  index:
  * @retval None
  */
static void PicturesPosition(uint32_t* x1, uint32_t* y1, uint32_t* x2, uint32_t* y2, uint32_t index)
{
  /* picture1 position */
  *x1 = index*5;
  *y1 = index;

  /* picture2 position */
  *x2 = 160 - index*5;
  *y2 = 32 - index;
}

/**
  * @brief  Reload Event callback.
  * @param  hltdc: pointer to a LTDC_HandleTypeDef structure that contains
  *                the configuration information for the LTDC.
  * @retval None
  */
void HAL_LTDC_ReloadEventCallback(LTDC_HandleTypeDef *hltdc)
{
  ReloadFlag = 1;
}

/**
  * @brief LCD Configuration.
  * @note  This function Configure the LTDC peripheral :
  *        1) Configure the Pixel Clock for the LCD
  *        2) Configure the LTDC Timing and Polarity
  *        3) Configure the LTDC Layer 1 :
  *           - indirect color (L8) as pixel format
  *           - The frame buffer is located at FLASH memory
  *           - The Layer size configuration : 320x240
  *        4) Configure the LTDC Layer 2 :
  *           - The frame buffer is located at FLASH memory
  *           - The Layer size configuration : 320x240
  *        5) Load 256 colors in CLUT address for Layer 1
  * @retval
  *  None
 */
static void LCD_Config(void)
{
  RCC_PeriphCLKInitTypeDef periph_clk_init_struct;

  LTDC_LayerCfgTypeDef      pLayerCfg;
  LTDC_LayerCfgTypeDef      pLayerCfg1;

/* LTDC Initialization -------------------------------------------------------*/

  /*## LTDC Clock Configuration ###########################################*/
  /* RK043FN48H LCD clock configuration */
  /* LCD clock configuration */
  /* PLL3_VCO Input = HSE_VALUE/PLL3M = 5 Mhz */
  /* PLL3_VCO Output = PLL3_VCO Input * PLL3N = 800 Mhz */
  /* PLLLCDCLK = PLL3_VCO Output/PLL3R = 800/83 = 9.63 Mhz */
  /* LTDC clock frequency = PLLLCDCLK = 9.63 Mhz */
  periph_clk_init_struct.PeriphClockSelection = RCC_PERIPHCLK_LTDC;
  periph_clk_init_struct.PLL3.PLL3M = 5;
  periph_clk_init_struct.PLL3.PLL3N = 160;
  periph_clk_init_struct.PLL3.PLL3FRACN = 0;
  periph_clk_init_struct.PLL3.PLL3P = 2;
  periph_clk_init_struct.PLL3.PLL3Q = 2;
  periph_clk_init_struct.PLL3.PLL3R = 83;
  periph_clk_init_struct.PLL3.PLL3VCOSEL = RCC_PLL3VCOWIDE;
  periph_clk_init_struct.PLL3.PLL3RGE = RCC_PLL3VCIRANGE_2;

  HAL_RCCEx_PeriphCLKConfig(&periph_clk_init_struct);

  /* LTDC Initialization -------------------------------------------------------*/
  /* DeInit */
  LtdcHandle.Instance = LTDC;
  HAL_LTDC_DeInit(&LtdcHandle);

  /* Polarity configuration */
  /* Initialize the horizontal synchronization polarity as active low */
  LtdcHandle.Init.HSPolarity = LTDC_HSPOLARITY_AL;
  /* Initialize the vertical synchronization polarity as active low */
  LtdcHandle.Init.VSPolarity = LTDC_VSPOLARITY_AL;
  /* Initialize the data enable polarity as active low */
  LtdcHandle.Init.DEPolarity = LTDC_DEPOLARITY_AL;
  /* Initialize the pixel clock polarity as input pixel clock */
  LtdcHandle.Init.PCPolarity = LTDC_PCPOLARITY_IPC;
  /* Timing configuration */
  /* The LCD AMPIRE 640x480 is selected */
  /* Timing configuration */
  LtdcHandle.Init.HorizontalSync = (RK043FN48H_HSYNC - 1);
  LtdcHandle.Init.VerticalSync = (RK043FN48H_VSYNC - 1);
  LtdcHandle.Init.AccumulatedHBP = (RK043FN48H_HSYNC + RK043FN48H_HBP - 1);
  LtdcHandle.Init.AccumulatedVBP = (RK043FN48H_VSYNC + RK043FN48H_VBP - 1);
  LtdcHandle.Init.AccumulatedActiveH = (RK043FN48H_HEIGHT + RK043FN48H_VSYNC + RK043FN48H_VBP - 1);
  LtdcHandle.Init.AccumulatedActiveW = (RK043FN48H_WIDTH + RK043FN48H_HSYNC + RK043FN48H_HBP - 1);
  LtdcHandle.Init.TotalHeigh = (RK043FN48H_HEIGHT + RK043FN48H_VSYNC + RK043FN48H_VBP + RK043FN48H_VFP - 1);
  LtdcHandle.Init.TotalWidth = (RK043FN48H_WIDTH + RK043FN48H_HSYNC + RK043FN48H_HBP + RK043FN48H_HFP - 1);

  /* Configure R,G,B component values for LCD background color */
  LtdcHandle.Init.Backcolor.Blue = 0;
  LtdcHandle.Init.Backcolor.Green = 0;
  LtdcHandle.Init.Backcolor.Red = 0;

  LtdcHandle.Instance = LTDC;

/* Layer1 Configuration ------------------------------------------------------*/

  /* Windowing configuration */
  pLayerCfg.WindowX0 = 0;
  pLayerCfg.WindowX1 = 320;
  pLayerCfg.WindowY0 = 0;
  pLayerCfg.WindowY1 = 240;

  /* Pixel Format configuration*/
  pLayerCfg.PixelFormat = LTDC_PIXEL_FORMAT_L8;

  /* Start Address configuration : frame buffer is located at FLASH memory */
  pLayerCfg.FBStartAdress = (uint32_t)&L8_320x240;

  /* Alpha constant (255 totally opaque) */
  pLayerCfg.Alpha = 255;

  /* Default Color configuration (configure A,R,G,B component values) */
  pLayerCfg.Alpha0 = 0;
  pLayerCfg.Backcolor.Blue = 0;
  pLayerCfg.Backcolor.Green = 0;
  pLayerCfg.Backcolor.Red = 0;

  /* Configure blending factors */
  pLayerCfg.BlendingFactor1 = LTDC_BLENDING_FACTOR1_PAxCA;
  pLayerCfg.BlendingFactor2 = LTDC_BLENDING_FACTOR2_PAxCA;

  /* Configure the number of lines and number of pixels per line */
  pLayerCfg.ImageWidth = 320;
  pLayerCfg.ImageHeight = 240;

/* Layer2 Configuration ------------------------------------------------------*/

  /* Windowing configuration */
  pLayerCfg1.WindowX0 = 160;
  pLayerCfg1.WindowX1 = 480;
  pLayerCfg1.WindowY0 = 32;
  pLayerCfg1.WindowY1 = 272;

  /* Pixel Format configuration*/
  pLayerCfg1.PixelFormat = LTDC_PIXEL_FORMAT_RGB565;

  /* Start Address configuration : frame buffer is located at FLASH memory */
  pLayerCfg1.FBStartAdress = (uint32_t)&RGB565_320x240;

  /* Alpha constant (255 totally opaque) */
  pLayerCfg1.Alpha = 200;

  /* Default Color configuration (configure A,R,G,B component values) */
  pLayerCfg1.Alpha0 = 0;
  pLayerCfg1.Backcolor.Blue = 0;
  pLayerCfg1.Backcolor.Green = 0;
  pLayerCfg1.Backcolor.Red = 0;

  /* Configure blending factors */
  pLayerCfg1.BlendingFactor1 = LTDC_BLENDING_FACTOR1_PAxCA;
  pLayerCfg1.BlendingFactor2 = LTDC_BLENDING_FACTOR2_PAxCA;

  /* Configure the number of lines and number of pixels per line */
  pLayerCfg1.ImageWidth = 320;
  pLayerCfg1.ImageHeight = 240;

  /* Configure the LTDC */
  if(HAL_LTDC_Init(&LtdcHandle) != HAL_OK)
  {
    /* Initialization Error */
    Error_Handler();
  }

  /* Configure the Background Layer*/
  if(HAL_LTDC_ConfigLayer(&LtdcHandle, &pLayerCfg, 0) != HAL_OK)
  {
    /* Initialization Error */
    Error_Handler();
  }

  /* Configure the Foreground Layer*/
  if(HAL_LTDC_ConfigLayer(&LtdcHandle, &pLayerCfg1, 1) != HAL_OK)
  {
    /* Initialization Error */
    Error_Handler();
  }
}

/**
* @brief  CPU L1-Cache enable.
* @param  None
* @retval None
*/
static void CPU_CACHE_Enable(void)
{
  /* Enable I-Cache */
  SCB_EnableICache();

  /* Enable D-Cache */
  SCB_EnableDCache();
}

/* USER CODE END 4 */

void Error_Handler(void)
{
  /* USER CODE BEGIN Error_Handler_Debug */
  /* User can add his own implementation to report the HAL error return state */
  __disable_irq();
  while (1)
  {
	    BSP_LED_Toggle(LED2);
  }
  /* USER CODE END Error_Handler_Debug */
}
